# STM32WLE4C8U6 register map
File version: 1.0
Registers are 32-bit, access not given, reset 0x0 unless marked. A register's access mark holds for its fields unless they carry their own. Offsets are from the block's base; [hi:lo] are bit positions; {n}, {i} and the like mark numbered series; 'fields as' and 'values as' point back to an identical list.

## VREFBUF
Base 0x40010030
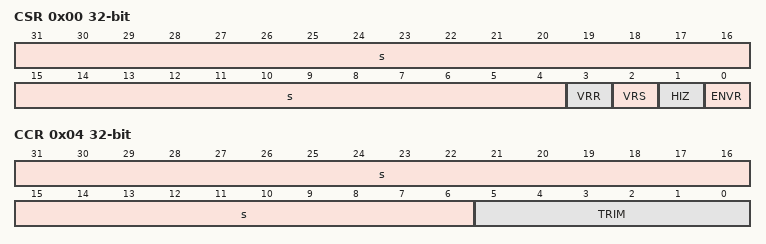
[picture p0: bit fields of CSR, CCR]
0x00 CSR
  [31:4] s, [3] VRR, [2] VRS, [1] HIZ, [0] ENVR
0x04 CCR
  [31:6] s, [5:0] TRIM

## COMP
Base 0x40010200
0x00 COMP1_CSR
  [31] LOCK, [30] VALUE, [26:25] INMESEL, [23] SCALEN, [22] BRGEN, [20:18] BLANKING, [17:16] HYST, [15] POLARITY, [8:7] INPSEL, [6:4] INMSEL, [3:2] PWRMODE, [29:1] s, [0] EN
0x04 COMP2_CSR
  [31] LOCK, [30] VALUE, [26:25] INMESEL, [23] SCALEN, [22] BRGEN, [20:18] BLANKING, [17:16] HYST, [15] POLARITY, [9] WINMODE, [8:7] INPSEL, [6:4] INMSEL, [3:2] PWRMODE, [29:1] s, [0] EN

## ADC
Base 0x40012400
0x00 ISR
  [13] CCRDY, [11] EOCAL, [9] AWD3, [8] AWD2, [7] AWD1, [31:5] s, [4] OVR, [3] EOS, [2] EOC, [1] EOSMP, [0] ADRDY
0x04 IER
  [13] CCRDYIE, [11] EOCALIE, [9] AWD3IE, [8] AWD2IE, [7] AWD1IE, [31:5] s, [4] OVRIE, [3] EOSIE, [2] EOCIE, [1] EOSMPIE, [0] ADRDYIE
0x08 CR
  [31] ADCAL, [28] ADVREGEN, [4] ADSTP, [30:3] s, [2] ADSTART, [1] ADDIS, [0] ADEN
0x0C CFGR1
  [30:26] AWDCH, [23] AWD1EN, [22] AWD1SGL, [21] CHSELRMOD, [16] DISCEN, [15] AUTOFF, [14] WAIT, [13] CONT, [12] OVRMOD, [11:10] EXTEN, [31:9] s, [8:6] EXTSEL, [5] ALIGN, [4:3] RES, [2] SCANDIR, [1] DMACFG, [0] DMAEN
0x10 CFGR2
  [31:30] CKMODE, [29] LFTRIG, [9] TOVS, [8:5] OVSS, [4:2] OVSR, [28:1] s, [0] OVSE
0x14 SMPR
  [n+8] SMPSEL{n} (n=0..17), [6:4] SMP2, [31:3] s, [2:0] SMP1
0x20 AWD1TR
  [27:16] HT1, [31:12] s, [11:0] LT1
0x24 AWD2TR
  [27:16] HT2, [31:12] s, [11:0] LT2
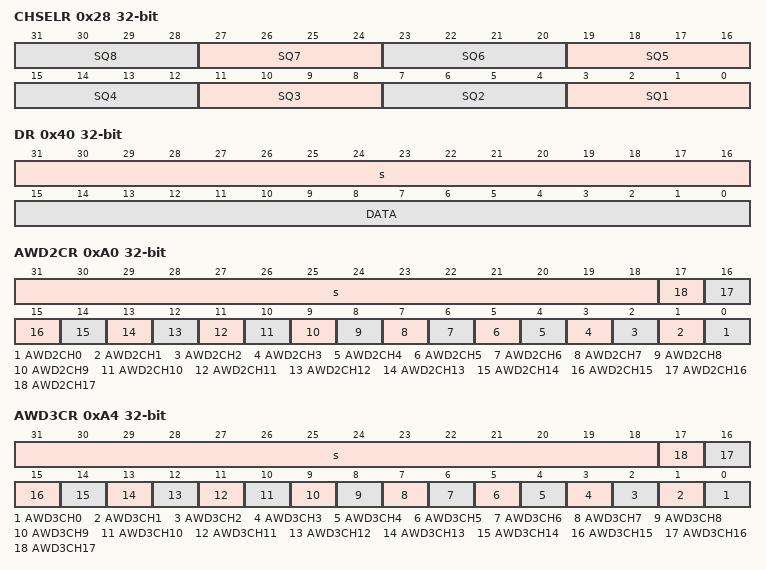
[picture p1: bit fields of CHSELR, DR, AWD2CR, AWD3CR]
0x28 CHSELR
  [4n-1:4n-4] SQ{n} (n=1..8)
0x2C AWD3TR
  [27:16] HT3, [31:12] s, [11:0] LT3
0x40 DR
  [31:16] s, [15:0] DATA
0xA0 AWD2CR
  [31:18] s, [n] AWD2CH{n} (n=0..17)
0xA4 AWD3CR
  [31:18] s, [n] AWD3CH{n} (n=0..17)
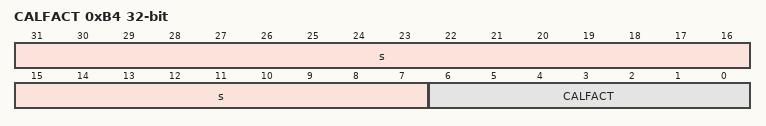
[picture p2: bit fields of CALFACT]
0xB4 CALFACT
  [31:7] s, [6:0] CALFACT
0x308 CCR
  [24] VBATEN, [23] TSEN, [22] VREFEN, [n+18] PRESC{n} (n=0..3), [31:0] s

## TIM16
Base 0x40014400
Same registers: TIM17 0x40014800
0x00 CR1
  [11] UIFREMA, [9:8] CKD, [7] ARPE, [31:4] s, [3] OPM, [2] URS, [1] UDIS, [0] CEN
0x04 CR2
  [9] OIS1N, [8] OIS1, [3] CCDS, [2] CCUS, [31:1] s, [0] CCPC
0x0C DIER
  [9] CC1DE, [8] UDE, [7] BIE, [5] COMIE, [31:2] s, [1] CC1IE, [0] UIE
0x10 SR
  [9] CC1OF, [7] BIF, [5] COMIF, [31:2] s, [1] CC1IF, [0] UIF
0x14 EGR
  [7] BG, [5] COMG, [31:2] s, [1] CC1G, [0] UG
0x18 CCMR1_OUT
  [31:7] s, [16:4] OC1M, [3] OC1PE, [2] OC1FE, [1:0] CC1S
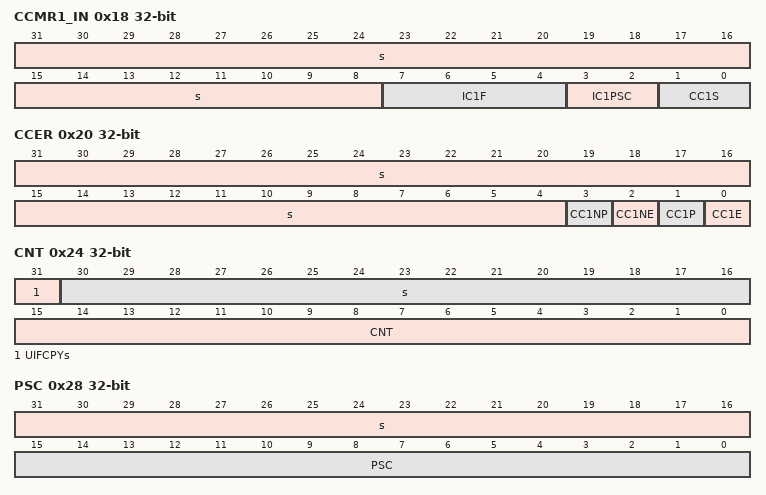
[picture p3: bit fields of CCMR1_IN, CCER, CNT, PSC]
0x18 CCMR1_IN
  [31:8] s, [7:4] IC1F, [3:2] IC1PSC, [1:0] CC1S
0x20 CCER
  [31:4] s, [3] CC1NP, [2] CC1NE, [1] CC1P, [0] CC1E
0x24 CNT
  [31] UIFCPYs, [30:16] s, [15:0] CNT
0x28 PSC
  [31:16] s, [15:0] PSC
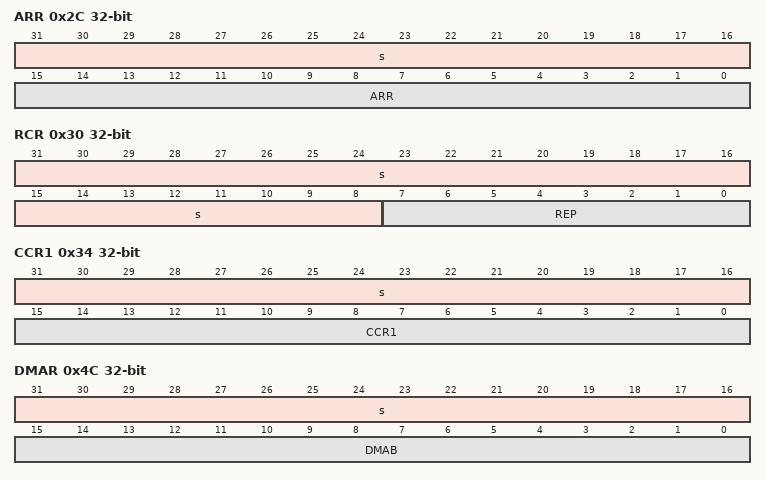
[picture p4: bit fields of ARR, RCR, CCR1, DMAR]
0x2C ARR
  [31:16] s, [15:0] ARR
0x30 RCR
  [31:8] s, [7:0] REP
0x34 CCR1
  [31:16] s, [15:0] CCR1
0x44 BDTR
  [28] BKBID, [26] BKDSRM, [31:16] s, [15] MOE, [14] AOE, [13] BKP, [12] BKE, [11] OSSR, [10] OSSI, [9:8] LOCK, [7:0] DTG
0x48 DCR
  [12:8] DBL, [31:5] s, [4:0] DBA
0x4C DMAR
  [31:16] s, [15:0] DMAB
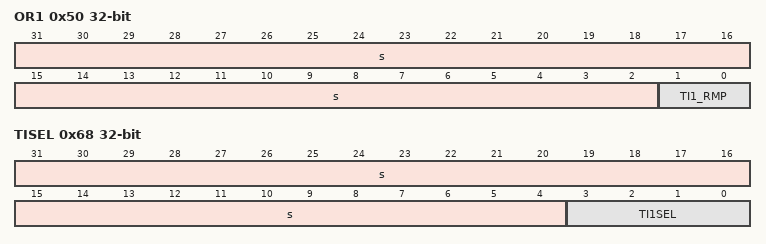
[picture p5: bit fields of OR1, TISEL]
0x50 OR1
  [31:2] s, [1:0] TI1_RMP
0x60 AF1
  [11] BKCMP2P, [10] BKCMP1P, [9] BKINP, [31:3] s, [2] BKCMP2E, [1] BKCMP1E, [0] BKINE
0x68 TISEL
  [31:4] s, [3:0] TI1SEL

## DMA1
Base 0x40020000
Same registers: DMA2 0x40020400
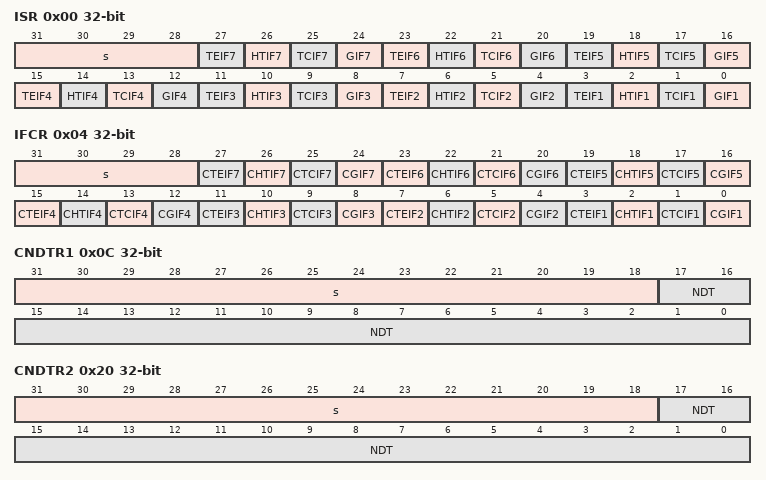
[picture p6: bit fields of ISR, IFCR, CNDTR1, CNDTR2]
0x00 ISR
  [31:28] s, [4n-1] TEIF{n} (n=1..7), [4n-2] HTIF{n} (n=1..7), [4n-3] TCIF{n} (n=1..7), [4n-4] GIF{n} (n=1..7)
0x04 IFCR
  [31:28] s, [4n-1] CTEIF{n} (n=1..7), [4n-2] CHTIF{n} (n=1..7), [4n-3] CTCIF{n} (n=1..7), [4n-4] CGIF{n} (n=1..7)
0x08 CCR1
  [20] PRIV, [31:15] s, [14] MEM2MEM, [13:12] PL, [11:10] MSIZE, [9:8] PSIZE, [7] MINC, [6] PINC, [5] CIRC, [4] DIR, [3] TEIE, [2] HTIE, [1] TCIE, [0] EN
0x0C CNDTR1
  [31:18] s, [17:0] NDT
0x10 CPAR1
  [31:0] PA
{0x0+0x14*i} CMAR{i} (i=1..7)
  [31:0] MA
0x1C CCR2
  fields as CCR1
0x20 CNDTR2
  [31:18] s, [17:0] NDT
0x24 CPAR2
  [31:0] PA
0x30 CCR3
  fields as CCR1
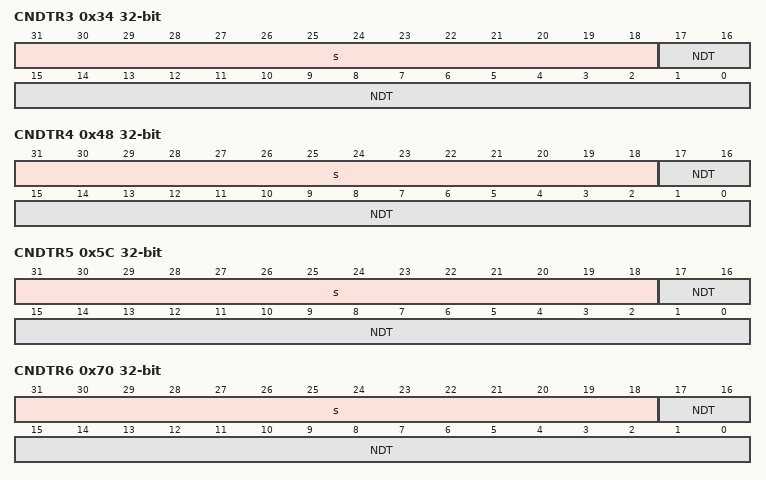
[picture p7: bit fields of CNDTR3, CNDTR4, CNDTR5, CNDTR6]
0x34 CNDTR3
  [31:18] s, [17:0] NDT
0x38 CPAR3
  [31:0] PA
0x44 CCR4
  fields as CCR1
0x48 CNDTR4
  [31:18] s, [17:0] NDT
0x4C CPAR4
  [31:0] PA
0x58 CCR5
  fields as CCR1
0x5C CNDTR5
  [31:18] s, [17:0] NDT
0x60 CPAR5
  [31:0] PA
0x6C CCR6
  fields as CCR1
0x70 CNDTR6
  [31:18] s, [17:0] NDT
0x74 CPAR6
  [31:0] PA
0x80 CCR7
  fields as CCR1
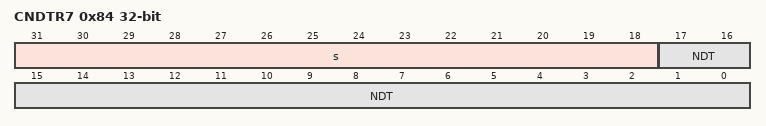
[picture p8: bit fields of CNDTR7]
0x84 CNDTR7
  [31:18] s, [17:0] NDT
0x88 CPAR7
  [31:0] PA
